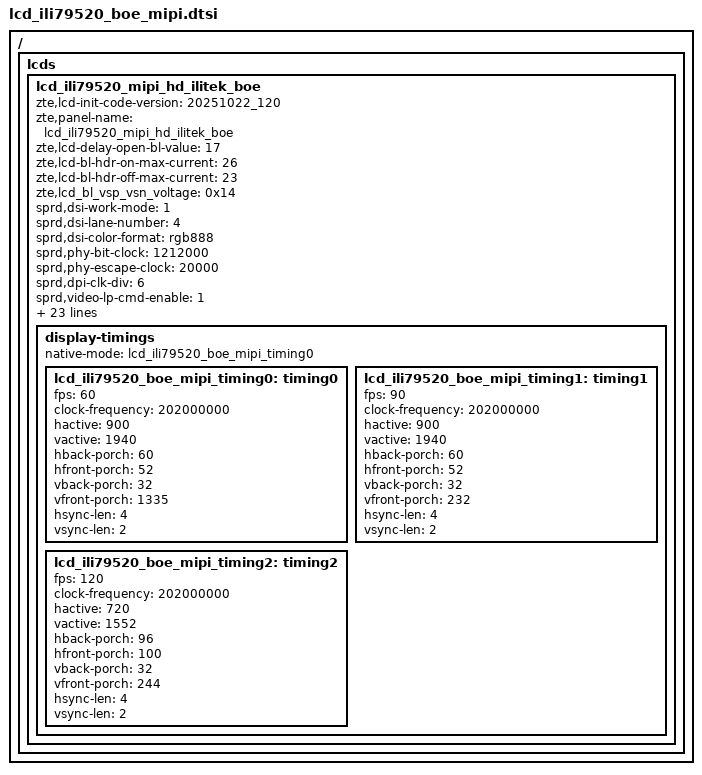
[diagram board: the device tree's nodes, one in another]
// SPDX-License-Identifier: GPL-2.0-only
/*
 * Unisoc ili79520 LCD config DTS file
 *
 * Copyright (C) 2021, Unisoc Inc.
 */
/ {
	fragment {
		target-path = "/";
		__overlay__ {
			lcds {
				lcd_ili79520_mipi_hd_ilitek_boe: lcd_ili79520_mipi_hd_ilitek_boe {
		zte,lcd-init-code-version = "20251022_120";
		zte,panel-name = "lcd_ili79520_mipi_hd_ilitek_boe";
		zte,lcd-delay-open-bl-value = <17>;
		zte,lcd-bl-hdr-on-max-current = <26>;
		zte,lcd-bl-hdr-off-max-current = <23>;
		zte,lcd_bl_vsp_vsn_voltage = <0x14>;

					sprd,dsi-work-mode = <1>; /* video burst mode*/
					sprd,dsi-lane-number = <4>;
					sprd,dsi-color-format = "rgb888";

					sprd,phy-bit-clock = <1212000>;  /* kbps */
					sprd,phy-escape-clock = <20000>;/* kHz */
					sprd,dpi-clk-div = <6>;
					sprd,video-lp-cmd-enable = <1>;
					sprd,hporch-lp-disable = <1>;

					sprd,width-mm = <7214>;/*zte mod for 6.75*/
					sprd,height-mm = <15551>;/*zte mod for 6.75*/
					sprd,esd-check-enable = <1>;
					sprd,esd-check-mode = <0>;  // 0:Reg mode 1:TE mode
					sprd,esd-check-period = <2000>;
					sprd,esd-check-register = <0x0A>;
					sprd,esd-check-value = <0x9C>;
					sprd,reset-on-sequence = <1 15>, <0 15>, <1 15>;
					sprd,reset-off-sequence = <1 5>;
					sprd,use-dcs-write;
					sprd,initial-command = [
39 00 00 04 FF 5A A5 01
39 00 00 02 00 53
39 00 00 02 01 17
39 00 00 02 02 00
39 00 00 02 03 00
39 00 00 02 04 CF
39 00 00 02 05 17
39 00 00 02 06 00
39 00 00 02 07 00
39 00 00 02 08 8D
39 00 00 02 09 02
39 00 00 02 0A F6
39 00 00 02 0B 00
39 00 00 02 0C 2A
39 00 00 02 0D 00
39 00 00 02 0E 00
39 00 00 02 0F 00
39 00 00 02 10 10
39 00 00 02 16 8D
39 00 00 02 17 02
39 00 00 02 18 76
39 00 00 02 19 00
39 00 00 02 1A 2A
39 00 00 02 1B 00
39 00 00 02 1C 00
39 00 00 02 1D 00
39 00 00 02 1E 10
39 00 00 02 28 8A
39 00 00 02 29 55
39 00 00 02 2A 8A
39 00 00 02 2B 55
39 00 00 02 92 8A
39 00 00 02 93 54
39 00 00 02 98 60
39 00 00 02 EE 10
39 00 00 02 EF 00
39 00 00 02 F0 00
39 00 00 02 31 2A
39 00 00 02 32 00
39 00 00 02 33 22
39 00 00 02 34 19
39 00 00 02 35 1B
39 00 00 02 36 1D
39 00 00 02 37 1F
39 00 00 02 38 11
39 00 00 02 39 13
39 00 00 02 3A 15
39 00 00 02 3B 17
39 00 00 02 3C 23
39 00 00 02 3D 09
39 00 00 02 3E 0D
39 00 00 02 3F 07
39 00 00 02 40 07
39 00 00 02 41 07
39 00 00 02 42 07
39 00 00 02 43 07
39 00 00 02 44 07
39 00 00 02 45 07
39 00 00 02 46 07
39 00 00 02 47 2A
39 00 00 02 48 00
39 00 00 02 49 22
39 00 00 02 4A 18
39 00 00 02 4B 1A
39 00 00 02 4C 1C
39 00 00 02 4D 1E
39 00 00 02 4E 10
39 00 00 02 4F 12
39 00 00 02 50 14
39 00 00 02 51 16
39 00 00 02 52 23
39 00 00 02 53 08
39 00 00 02 54 0C
39 00 00 02 55 07
39 00 00 02 56 07
39 00 00 02 57 07
39 00 00 02 58 07
39 00 00 02 59 07
39 00 00 02 5A 07
39 00 00 02 5B 07
39 00 00 02 5C 07
39 00 00 02 61 2A
39 00 00 02 62 00
39 00 00 02 63 22
39 00 00 02 64 16
39 00 00 02 65 14
39 00 00 02 66 12
39 00 00 02 67 10
39 00 00 02 68 1E
39 00 00 02 69 1C
39 00 00 02 6A 1A
39 00 00 02 6B 18
39 00 00 02 6C 23
39 00 00 02 6D 0C
39 00 00 02 6E 08
39 00 00 02 6F 07
39 00 00 02 70 07
39 00 00 02 71 07
39 00 00 02 72 07
39 00 00 02 73 07
39 00 00 02 74 07
39 00 00 02 75 07
39 00 00 02 76 07
39 00 00 02 77 2A
39 00 00 02 78 00
39 00 00 02 79 22
39 00 00 02 7A 17
39 00 00 02 7B 15
39 00 00 02 7C 13
39 00 00 02 7D 11
39 00 00 02 7E 1F
39 00 00 02 7F 1D
39 00 00 02 80 1B
39 00 00 02 81 19
39 00 00 02 82 23
39 00 00 02 83 0D
39 00 00 02 84 09
39 00 00 02 85 07
39 00 00 02 86 07
39 00 00 02 87 07
39 00 00 02 88 07
39 00 00 02 89 07
39 00 00 02 8A 07
39 00 00 02 8B 07
39 00 00 02 8C 07
39 00 00 02 D1 10
39 00 00 02 D3 10
39 00 00 02 D5 00
39 00 00 02 D8 00
39 00 00 02 DA 00
39 00 00 02 DC B7
39 00 00 02 DD 08
39 00 00 02 99 40
39 00 00 02 E0 5E
39 00 00 02 E2 32
39 00 00 02 E3 01
39 00 00 02 E6 22
39 00 00 02 E7 54
39 00 00 02 C1 00
39 00 00 02 C3 00
39 00 00 02 F8 08
39 00 00 04 FF 5A A5 11
39 00 00 02 00 3A
39 00 00 02 01 00
39 00 00 02 02 3A
39 00 00 02 03 00
39 00 00 02 08 10
39 00 00 02 0C 10
39 00 00 04 FF 5A A5 02
39 00 00 02 06 00
39 00 00 02 07 F1
39 00 00 02 39 00
39 00 00 02 3A 89
39 00 00 02 3B 00
39 00 00 02 3C 22
39 00 00 02 3D 00
39 00 00 02 3E F0
39 00 00 04 FF 5A A5 12
39 00 00 02 01 00
39 00 00 02 02 F1
39 00 00 02 10 00
39 00 00 02 11 98
39 00 00 02 12 00
39 00 00 02 13 16
39 00 00 02 14 00
39 00 00 02 15 E6
39 00 00 04 FF 5A A5 02
39 00 00 02 1B 90
39 00 00 02 4D 8E
39 00 00 02 51 20
39 00 00 02 68 44
39 00 00 02 43 1A
39 00 00 02 40 06
39 00 00 02 4E 44
39 00 00 02 29 48
39 00 00 02 2A 48
39 00 00 02 02 21
39 00 00 02 0C 02
39 00 00 04 FF 5A A5 03
39 00 00 02 59 02
39 00 00 02 5A D0
39 00 00 02 5B 06
39 00 00 02 5C 10
39 00 00 04 FF 5A A5 03
39 00 00 02 35 00
39 00 00 02 36 04
39 00 00 02 37 05
39 00 00 02 4C 00
39 00 00 02 4D CC
39 00 00 02 4E CC
39 00 00 02 61 00
39 00 00 02 62 05
39 00 00 02 63 CC
39 00 00 02 64 CC
39 00 00 02 65 00
39 00 00 02 66 05
39 00 00 02 67 CC
39 00 00 02 68 CC
39 00 00 02 69 33
39 00 00 04 FF 5A A5 14
39 00 00 02 86 01
39 00 00 02 87 1D
39 00 00 04 FF 5A A5 05
39 00 00 02 55 61
39 00 00 02 56 4D
39 00 00 02 5A B5
39 00 00 02 60 BB
39 00 00 02 66 A1
39 00 00 02 6C 93
39 00 00 02 54 87
39 00 00 02 1E 0B
39 00 00 02 53 0A
39 00 00 02 44 4A
39 00 00 04 FF 5A A5 06
39 00 00 02 D9 1F
39 00 00 02 C0 94
39 00 00 02 C1 07
39 00 00 02 CA 84
39 00 00 02 CB 03
39 00 00 02 48 05
39 00 00 02 C7 01
39 00 00 02 3E 62
39 00 00 04 FF 5A A5 07
39 00 00 02 35 80
39 00 00 02 41 03
39 00 00 02 42 50
39 00 00 04 FF 5A A5 08
39 00 00 1E E0 00 00 18 4E 83 50 C6 FC 27 5B 95 83 C4 F8 26 AA 52 7F B4 D4 FE FD 1E 49 7E 3F A8 D1 DA
39 00 00 1E E1 00 00 18 4E 83 50 C6 FC 27 5B 95 83 C4 F8 26 AA 52 7F B4 D4 FE FD 1E 49 7E 3F A8 D1 DA
39 00 00 04 FF 5A A5 0B
39 00 00 02 9A 4A
39 00 00 02 9B 20
39 00 00 02 9C 07
39 00 00 02 9D 07
39 00 00 02 9E FD
39 00 00 02 9F FD
39 00 00 02 94 49
39 00 00 02 95 1B
39 00 00 02 96 06
39 00 00 02 97 06
39 00 00 02 98 E3
39 00 00 02 99 E3
39 00 00 02 BC 22
39 00 00 02 BD E0
39 00 00 04 FF 5A A5 0E
39 00 00 02 17 10
39 00 00 02 5D 08
39 00 00 04 FF 5A A5 0E
39 00 00 02 14 15
39 00 00 02 12 02
39 00 00 02 3D 02
39 00 00 02 00 80
39 00 00 04 FF 5A A5 00
39 00 00 02 35 00
39 78 00 02 11 00
39 14 00 02 29 00
						];
zte,initial-command-fps120 = [
39 00 00 04 FF 5A A5 01
39 00 00 02 00 53
39 00 00 02 01 17
39 00 00 02 02 00
39 00 00 02 03 00
39 00 00 02 04 CF
39 00 00 02 05 17
39 00 00 02 06 00
39 00 00 02 07 00
39 00 00 02 08 8D
39 00 00 02 09 02
39 00 00 02 0A F6
39 00 00 02 0B 00
39 00 00 02 0C 2A
39 00 00 02 0D 00
39 00 00 02 0E 00
39 00 00 02 0F 00
39 00 00 02 10 10
39 00 00 02 16 8D
39 00 00 02 17 02
39 00 00 02 18 76
39 00 00 02 19 00
39 00 00 02 1A 2A
39 00 00 02 1B 00
39 00 00 02 1C 00
39 00 00 02 1D 00
39 00 00 02 1E 10
39 00 00 02 28 8A
39 00 00 02 29 55
39 00 00 02 2A 8A
39 00 00 02 2B 55
39 00 00 02 92 8A
39 00 00 02 93 54
39 00 00 02 98 60
39 00 00 02 EE 10
39 00 00 02 EF 00
39 00 00 02 F0 00
39 00 00 02 31 2A
39 00 00 02 32 00
39 00 00 02 33 22
39 00 00 02 34 19
39 00 00 02 35 1B
39 00 00 02 36 1D
39 00 00 02 37 1F
39 00 00 02 38 11
39 00 00 02 39 13
39 00 00 02 3A 15
39 00 00 02 3B 17
39 00 00 02 3C 23
39 00 00 02 3D 09
39 00 00 02 3E 0D
39 00 00 02 3F 07
39 00 00 02 40 07
39 00 00 02 41 07
39 00 00 02 42 07
39 00 00 02 43 07
39 00 00 02 44 07
39 00 00 02 45 07
39 00 00 02 46 07
39 00 00 02 47 2A
39 00 00 02 48 00
39 00 00 02 49 22
39 00 00 02 4A 18
39 00 00 02 4B 1A
39 00 00 02 4C 1C
39 00 00 02 4D 1E
39 00 00 02 4E 10
39 00 00 02 4F 12
39 00 00 02 50 14
39 00 00 02 51 16
39 00 00 02 52 23
39 00 00 02 53 08
39 00 00 02 54 0C
39 00 00 02 55 07
39 00 00 02 56 07
39 00 00 02 57 07
39 00 00 02 58 07
39 00 00 02 59 07
39 00 00 02 5A 07
39 00 00 02 5B 07
39 00 00 02 5C 07
39 00 00 02 61 2A
39 00 00 02 62 00
39 00 00 02 63 22
39 00 00 02 64 16
39 00 00 02 65 14
39 00 00 02 66 12
39 00 00 02 67 10
39 00 00 02 68 1E
39 00 00 02 69 1C
39 00 00 02 6A 1A
39 00 00 02 6B 18
39 00 00 02 6C 23
39 00 00 02 6D 0C
39 00 00 02 6E 08
39 00 00 02 6F 07
39 00 00 02 70 07
39 00 00 02 71 07
39 00 00 02 72 07
39 00 00 02 73 07
39 00 00 02 74 07
39 00 00 02 75 07
39 00 00 02 76 07
39 00 00 02 77 2A
39 00 00 02 78 00
39 00 00 02 79 22
39 00 00 02 7A 17
39 00 00 02 7B 15
39 00 00 02 7C 13
39 00 00 02 7D 11
39 00 00 02 7E 1F
39 00 00 02 7F 1D
39 00 00 02 80 1B
39 00 00 02 81 19
39 00 00 02 82 23
39 00 00 02 83 0D
39 00 00 02 84 09
39 00 00 02 85 07
39 00 00 02 86 07
39 00 00 02 87 07
39 00 00 02 88 07
39 00 00 02 89 07
39 00 00 02 8A 07
39 00 00 02 8B 07
39 00 00 02 8C 07
39 00 00 02 D1 10
39 00 00 02 D3 10
39 00 00 02 D5 00
39 00 00 02 D8 00
39 00 00 02 DA 00
39 00 00 02 DC B7
39 00 00 02 DD 08
39 00 00 02 99 40
39 00 00 02 E0 5E
39 00 00 02 E2 32
39 00 00 02 E3 01
39 00 00 02 E6 22
39 00 00 02 E7 54
39 00 00 02 C1 00
39 00 00 02 C3 00
39 00 00 02 F8 08
39 00 00 04 FF 5A A5 11
39 00 00 02 00 3A
39 00 00 02 01 00
39 00 00 02 02 3A
39 00 00 02 03 00
39 00 00 02 08 10
39 00 00 02 0C 10
39 00 00 04 FF 5A A5 02
39 00 00 02 06 00
39 00 00 02 07 F1
39 00 00 02 39 00
39 00 00 02 3A 89
39 00 00 02 3B 00
39 00 00 02 3C 22
39 00 00 02 3D 00
39 00 00 02 3E F0
39 00 00 04 FF 5A A5 12
39 00 00 02 01 00
39 00 00 02 02 F1
39 00 00 02 10 00
39 00 00 02 11 98
39 00 00 02 12 00
39 00 00 02 13 16
39 00 00 02 14 00
39 00 00 02 15 E6
39 00 00 04 FF 5A A5 02
39 00 00 02 1B 80
39 00 00 02 4D 8E
39 00 00 02 51 20
39 00 00 02 68 44
39 00 00 02 43 1A
39 00 00 02 40 06
39 00 00 02 4E 44
39 00 00 02 29 48
39 00 00 02 2A 48
39 00 00 02 02 21
39 00 00 02 0C 02
39 00 00 04 FF 5A A5 03
39 00 00 02 59 02
39 00 00 02 5A D0
39 00 00 02 5B 06
39 00 00 02 5C 10
39 00 00 04 FF 5A A5 03
39 00 00 02 35 00
39 00 00 02 36 04
39 00 00 02 37 05
39 00 00 02 4C 00
39 00 00 02 4D CC
39 00 00 02 4E CC
39 00 00 02 60 01
39 00 00 02 61 00
39 00 00 02 62 05
39 00 00 02 63 CC
39 00 00 02 64 CC
39 00 00 02 65 00
39 00 00 02 66 05
39 00 00 02 67 CC
39 00 00 02 68 CC
39 00 00 02 69 33
39 00 00 04 FF 5A A5 14
39 00 00 02 86 01
39 00 00 02 87 1D
39 00 00 04 FF 5A A5 05
39 00 00 02 55 61
39 00 00 02 56 4D
39 00 00 02 5A B5
39 00 00 02 60 BB
39 00 00 02 66 A1
39 00 00 02 6C 93
39 00 00 02 54 87
39 00 00 02 1E 0B
39 00 00 02 53 0A
39 00 00 02 44 4A
39 00 00 04 FF 5A A5 06
39 00 00 02 D9 1F
39 00 00 02 C0 94
39 00 00 02 C1 07
39 00 00 02 CA 84
39 00 00 02 CB 03
39 00 00 02 48 05
39 00 00 02 C7 01
39 00 00 02 3E 62
39 00 00 04 FF 5A A5 07
39 00 00 02 35 80
39 00 00 02 41 03
39 00 00 02 42 50
39 00 00 04 FF 5A A5 08
39 00 00 1E E0 00 00 18 4E 83 50 C6 FC 27 5B 95 83 C4 F8 26 AA 52 7F B4 D4 FE FD 1E 49 7E 3F A8 D1 DA
39 00 00 1E E1 00 00 18 4E 83 50 C6 FC 27 5B 95 83 C4 F8 26 AA 52 7F B4 D4 FE FD 1E 49 7E 3F A8 D1 DA
39 00 00 04 FF 5A A5 0B
39 00 00 02 9A 4A
39 00 00 02 9B 20
39 00 00 02 9C 07
39 00 00 02 9D 07
39 00 00 02 9E FD
39 00 00 02 9F FD
39 00 00 02 94 49
39 00 00 02 95 1B
39 00 00 02 96 06
39 00 00 02 97 06
39 00 00 02 98 E3
39 00 00 02 99 E3
39 00 00 02 BC 22
39 00 00 02 BD E0
39 00 00 04 FF 5A A5 0E
39 00 00 02 17 10
39 00 00 02 5D 08
39 00 00 04 FF 5A A5 0E
39 00 00 02 14 15
39 00 00 02 12 02
39 00 00 02 3D 02
39 00 00 02 00 80
39 00 00 04 FF 5A A5 00
39 00 00 02 35 00
39 78 00 02 11 00
39 14 00 02 29 00
];

zte,fps90-to-fps60 = [
39 00 00 04 FF 5A A5 02
39 00 00 02 1B 90
39 00 00 04 FF 5A A5 03
39 00 00 02 60 00
39 05 00 04 FF 5A A5 00
];

zte,fps-to-fps120 = [
39 00 00 04 FF 5A A5 02
39 00 00 02 1B 80
39 00 00 04 FF 5A A5 03
39 00 00 02 60 01
39 05 00 04 FF 5A A5 00
];
					sprd,sleep-in-command = [
						39 0A 00 04 FF 5A A5 00
						13 14 00 01 28
						13 78 00 01 10
						];
					sprd,sleep-out-command = [
						13 78 00 01 11
						13 64 00 01 29
						];

					display-timings {
						native-mode = <&lcd_ili79520_boe_mipi_timing0>;

						lcd_ili79520_boe_mipi_timing0: timing0 {
							fps = <60>;
							clock-frequency = <202000000>;
							hactive = <900>;
							vactive = <1940>;
							hback-porch = <60>;
							hfront-porch = <52>;
							vback-porch = <32>;
							vfront-porch = <1335>;
							hsync-len = <4>;
							vsync-len = <2>;
						};
						lcd_ili79520_boe_mipi_timing1: timing1 {
							fps = <90>;
							clock-frequency = <202000000>;
							hactive = <900>;
							vactive = <1940>;
							hback-porch = <60>;
							hfront-porch = <52>;
							vback-porch = <32>;
							vfront-porch = <232>;
							hsync-len = <4>;
							vsync-len = <2>;
						};
						lcd_ili79520_boe_mipi_timing2: timing2 {
							fps = <120>;
							clock-frequency = <202000000>;
							hactive = <720>;
							vactive = <1552>;
							hback-porch = <96>;
							hfront-porch = <100>;
							vback-porch = <32>;
							vfront-porch = <244>;
							hsync-len = <4>;
							vsync-len = <2>;
						};
					};
				};
			};
		};
	};
};
